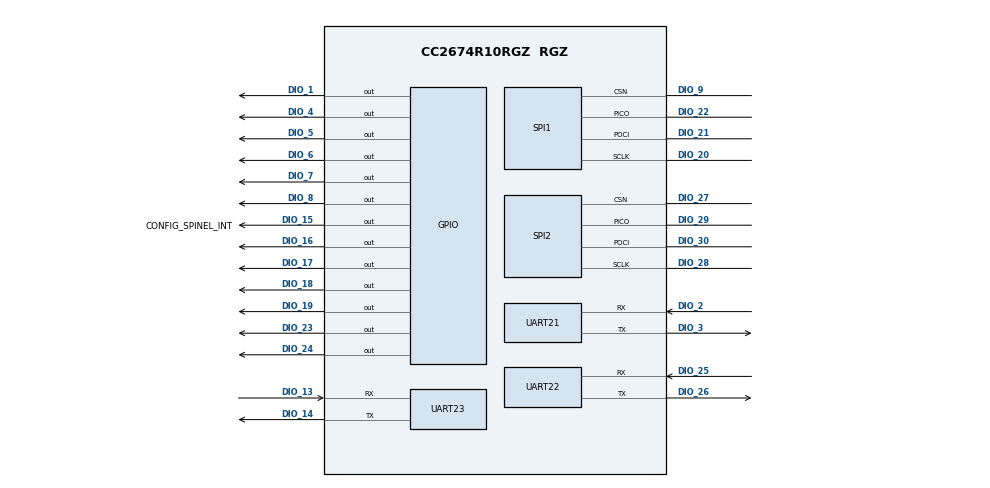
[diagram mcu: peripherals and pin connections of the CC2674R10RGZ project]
/**
 * @cliArgs --device "CC2674R10RGZ" --package "RGZ" --part "Default" --rtos "freertos" --product "simplelink_cc13xx_cc26xx_sdk@7.10.01.24"
 * @versions {"tool":"1.16.2+3028"}
 */

/**
 * Import the modules used in this configuration.
 */
const CCFG      = scripting.addModule("/ti/devices/CCFG");
const custom    = scripting.addModule("/ti/devices/radioconfig/custom");
const rfdesign  = scripting.addModule("/ti/devices/radioconfig/rfdesign");
const AESECB    = scripting.addModule("/ti/drivers/AESECB");
const AESECB1   = AESECB.addInstance();
const DMA       = scripting.addModule("/ti/drivers/DMA");
const ECDH      = scripting.addModule("/ti/drivers/ECDH");
const ECDH1     = ECDH.addInstance();
const ECDSA     = scripting.addModule("/ti/drivers/ECDSA");
const ECDSA1    = ECDSA.addInstance();
const ECJPAKE   = scripting.addModule("/ti/drivers/ECJPAKE");
const ECJPAKE1  = ECJPAKE.addInstance();
const GPIO      = scripting.addModule("/ti/drivers/GPIO");
const GPIO1     = GPIO.addInstance();
const GPIO2     = GPIO.addInstance();
const GPIO3     = GPIO.addInstance();
const GPIO4     = GPIO.addInstance();
const GPIO5     = GPIO.addInstance();
const GPIO6     = GPIO.addInstance();
const GPIO7     = GPIO.addInstance();
const GPIO8     = GPIO.addInstance();
const GPIO9     = GPIO.addInstance();
const GPIO10    = GPIO.addInstance();
const GPIO11    = GPIO.addInstance();
const GPIO12    = GPIO.addInstance();
const GPIO13    = GPIO.addInstance();
const NVS       = scripting.addModule("/ti/drivers/NVS");
const NVS1      = NVS.addInstance();
const Power     = scripting.addModule("/ti/drivers/Power");
const RF        = scripting.addModule("/ti/drivers/RF");
const SHA2      = scripting.addModule("/ti/drivers/SHA2");
const SHA21     = SHA2.addInstance();
const SPI       = scripting.addModule("/ti/drivers/SPI");
const SPI1      = SPI.addInstance();
const SPI2      = SPI.addInstance();
const TRNG      = scripting.addModule("/ti/drivers/TRNG");
const TRNG1     = TRNG.addInstance();
const UART2     = scripting.addModule("/ti/drivers/UART2");
const UART21    = UART2.addInstance();
const UART22    = UART2.addInstance();
const UART23    = UART2.addInstance();
const Watchdog  = scripting.addModule("/ti/drivers/Watchdog");
const Watchdog1 = Watchdog.addInstance();

/**
 * Write custom configuration values to the imported modules.
 */
CCFG.xoscCapArrayDelta       = 0xD5;
CCFG.enableBootloader        = true;
CCFG.dioBootloaderBackdoor   = 15;
CCFG.levelBootloaderBackdoor = "Active low";
CCFG.srcClkLF                = "Derived from HF XOSC";
CCFG.ccfgTemplate.$name      = "ti_devices_CCFG_CCFGCC26XXTemplate0";

custom.ieee                                                  = ["ieee154"];
custom.radioConfigieee154.$name                              = "ti_devices_radioconfig_settings_ieee_15_40";
custom.radioConfigieee154.codeExportConfig.$name             = "ti_devices_radioconfig_code_export_param0";
custom.radioConfigieee154.codeExportConfig.useConst          = true;
custom.radioConfigieee154.codeExportConfig.useMulti          = true;
custom.radioConfigieee154.codeExportConfig.symGenMethod      = "Custom";
custom.radioConfigieee154.codeExportConfig.cmdList_ieee_15_4 = ["cmdFs","cmdIeeeCsma","cmdIeeeEdScan","cmdIeeeRx","cmdIeeeRxAck","cmdIeeeTx","cmdRadioSetup","cmdTxTest"];
custom.radioConfigieee154.codeExportConfig.cmdRadioSetup     = "RF_cmdIeeeRadioSetup";

AESECB1.$name = "CONFIG_AESECB_MBEDTLS";

ECDH1.$name = "CONFIG_ECDH_0";

ECDSA1.$name = "CONFIG_ECDSA_0";

ECJPAKE1.$name = "CONFIG_ECJPAKE_0";

GPIO1.mode            = "Output";
GPIO1.$name           = "CONFIG_GPIO_GREEN_LED";
GPIO1.gpioPin.$assign = "DIO_16";

GPIO2.$name              = "CONFIG_SPINEL_INT";
GPIO2.mode               = "Output";
GPIO2.outputStrength     = "High";
GPIO2.initialOutputState = "High";
GPIO2.gpioPin.$assign    = "DIO_15";

GPIO3.$name           = "CONFIG_GPIO_SENSOR_CORE_RF_WAKE";
GPIO3.gpioPin.$assign = "DIO_24";

GPIO4.$name           = "CONFIG_GPIO_SENSOR_CORE_RF_WAKE_NIRQ";
GPIO4.gpioPin.$assign = "DIO_23";

GPIO5.$name           = "CONFIG_GPIO_COEX_RQST";
GPIO5.mode            = "Output";
GPIO5.gpioPin.$assign = "DIO_17";

GPIO6.$name           = "CONFIG_GPIO_COEX_PRIO";
GPIO6.mode            = "Output";
GPIO6.gpioPin.$assign = "DIO_18";

GPIO7.$name           = "CONFIG_GPIO_COEX_GNT";
GPIO7.gpioPin.$assign = "DIO_19";

GPIO8.$name              = "CONFIG_GPIO_FEM_CHL";
GPIO8.mode               = "Output";
GPIO8.initialOutputState = "High";
GPIO8.gpioPin.$assign    = "DIO_4";

GPIO9.$name              = "CONFIG_GPIO_FEM_CTX";
GPIO9.mode               = "Output";
GPIO9.initialOutputState = "High";
GPIO9.gpioPin.$assign    = "DIO_7";

GPIO10.$name           = "CONFIG_GPIO_FEM_CPS";
GPIO10.mode            = "Output";
GPIO10.gpioPin.$assign = "DIO_8";

GPIO11.$name           = "CONFIG_GPIO_FEM_CRX";
GPIO11.mode            = "Output";
GPIO11.gpioPin.$assign = "DIO_5";

GPIO12.$name              = "CONFIG_GPIO_FEM_CSD";
GPIO12.mode               = "Output";
GPIO12.initialOutputState = "High";
GPIO12.gpioPin.$assign    = "DIO_1";

GPIO13.$name           = "CONFIG_GPIO_FEM_ANT_SELECT";
GPIO13.mode            = "Output";
GPIO13.gpioPin.$assign = "DIO_6";

NVS1.$name                    = "CONFIG_NVSINTERNAL";
NVS1.internalFlash.$name      = "ti_drivers_nvs_NVSCC26XX0";
NVS1.internalFlash.regionBase = 0x52000;
NVS1.internalFlash.regionSize = 0x4000;

SHA21.$name = "CONFIG_SHA2_0";

SPI1.mode                = "Four Pin CS Active Low";
SPI1.$name               = "CONFIG_SPI_VOICE_IC";
SPI1.spi.sclkPin.$assign = "DIO_20";
SPI1.spi.pociPin.$assign = "DIO_21";
SPI1.spi.picoPin.$assign = "DIO_22";
SPI1.spi.csnPin.$assign  = "DIO_9";

SPI2.$name               = "CONFIG_SPI_EXT_FLASH";
SPI2.mode                = "Four Pin CS Active Low";
SPI2.spi.sclkPin.$assign = "DIO_28";
SPI2.spi.pociPin.$assign = "DIO_30";
SPI2.spi.picoPin.$assign = "DIO_29";
SPI2.spi.csnPin.$assign  = "DIO_27";

TRNG1.$name = "CONFIG_TRNG_THREAD";

UART21.$name              = "CONFIG_UART2_DEBUG_UART";
UART21.uart.$assign       = "UART0";
UART21.uart.txPin.$assign = "DIO_3";
UART21.uart.rxPin.$assign = "DIO_2";

UART22.$name              = "CONFIG_UART2_SENSOR_CORE";
UART22.uart.txPin.$assign = "DIO_26";
UART22.uart.rxPin.$assign = "DIO_25";

UART23.$name              = "CONFIG_UART2_E2C_CORE";
UART23.uart.txPin.$assign = "DIO_14";
UART23.uart.rxPin.$assign = "DIO_13";

Watchdog1.$name            = "CONFIG_WATCHDOG0";
Watchdog1.watchdog.$assign = "WDT0";

/**
 * Pinmux solution for unlocked pins/peripherals. This ensures that minor changes to the automatic solver in a future
 * version of the tool will not impact the pinmux you originally saw.  These lines can be completely deleted in order to
 * re-solve from scratch.
 */
SPI1.spi.$suggestSolution              = "SPI2";
SPI1.spi.dmaRxChannel.$suggestSolution = "DMA_CH19";
SPI1.spi.dmaTxChannel.$suggestSolution = "DMA_CH20";
SPI2.spi.$suggestSolution              = "SPI1";
SPI2.spi.dmaRxChannel.$suggestSolution = "DMA_CH16";
SPI2.spi.dmaTxChannel.$suggestSolution = "DMA_CH17";
UART22.uart.$suggestSolution           = "UART2";
UART23.uart.$suggestSolution           = "UART1";
